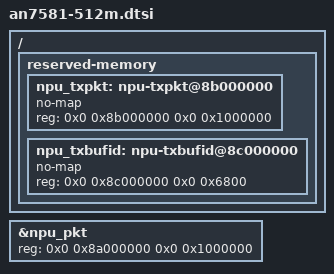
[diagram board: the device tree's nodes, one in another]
// SPDX-License-Identifier: (GPL-2.0-only OR BSD-2-Clause)

#include "an7581.dtsi"

&npu_pkt {
	reg = <0x0 0x8a000000 0x0 0x1000000>;
};

/ {
	reserved-memory {
		/* Delete nodes with old unit addresses to avoid duplicates and mismatches */
		/delete-node/ npu-txpkt@8cc00000;
		/delete-node/ npu-txbufid@90c00000;

		/* Define new nodes with correct unit addresses for 512M layout */
		npu_txpkt: npu-txpkt@8b000000 {
			no-map;
			reg = <0x0 0x8b000000 0x0 0x1000000>;
		};

		npu_txbufid: npu-txbufid@8c000000 {
			no-map;
			reg = <0x0 0x8c000000 0x0 0x6800>;
		};
	};
};
